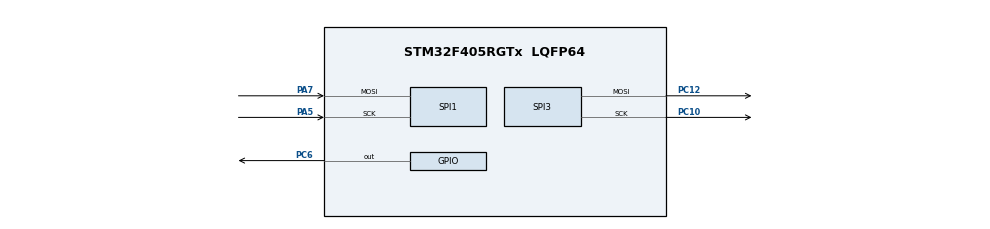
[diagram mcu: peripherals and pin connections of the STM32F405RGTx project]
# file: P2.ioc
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Mcu.Family=STM32F4
Mcu.Name=STM32F405RGTx
Mcu.Package=LQFP64
NVIC.PriorityGroup=NVIC_PRIORITYGROUP_4
PA5.Mode=RX_Only_Simplex_Unidirect_Slave
PA5.Signal=SPI1_SCK
PA7.Mode=RX_Only_Simplex_Unidirect_Slave
PA7.Signal=SPI1_MOSI
PC10.Mode=TX_Only_Simplex_Unidirect_Master
PC10.Signal=SPI3_SCK
PC12.Mode=TX_Only_Simplex_Unidirect_Master
PC12.Signal=SPI3_MOSI
PC6.Signal=GPIO_Output
ProjectManager.TargetToolchain=EWARM 6.70
RCC.48MHZClocksFreq_Value=48000000
RCC.AHBFreq_Value=16000000
RCC.APB1Freq_Value=16000000
RCC.APB2Freq_Value=16000000
RCC.EnableExtClockForI2S-ClockTree=false
RCC.EnableHSE-ClockTree=false
RCC.EnableHSERTCDevisor-ClockTree=false
RCC.EnableLSE-ClockTree=false
RCC.EnableLSERTC-ClockTree=false
RCC.ExtClockEnable-ClockTree=false
RCC.FLatency-AdvancedSettings=FLASH_LATENCY_0
RCC.HSEState-ClockTree=RCC_HSE_OFF
RCC.HSE_VALUE=25000000
RCC.HSIState-ClockTree=RCC_HSI_ON
RCC.HSI_VALUE=16000000
RCC.I2SEnable-ClockTree=false
RCC.IWDGEnable-ClockTree=false
RCC.LSE_VALUE=32768
RCC.LSIState-ClockTree=RCC_LSI_OFF
RCC.MCO1OutPutEnable-ClockTree=false
RCC.MCO2OutPutEnable-ClockTree=false
RCC.OscillatorTypeHSI-ClockTree=RCC_OSCILLATORTYPE_HSI
RCC.PLLState-ClockTree=RCC_PLL_OFF
RCC.PWR_Regulator_Voltage_Scale-AdvancedSettings=PWR_REGULATOR_VOLTAGE_SCALE2
RCC.RNGEnable-ClockTree=false
RCC.RTCEnable-ClockTree=false
RCC.SDIOEnable-ClockTree=false
RCC.SYSCLKFreq_VALUE=16000000
RCC.USBFSEnable-ClockTree=false
RCC.USBHSEnable-ClockTree=false
RCC.VCOOutputFreq_Value=192000000
SPI1.CalculateBaudRate-RX_Only_Simplex_Unidirect_Slave=8.0 MBits/s
SPI1.Direction-RX_Only_Simplex_Unidirect_Slave=SPI_DIRECTION_2LINES_RXONLY
SPI1.Mode-RX_Only_Simplex_Unidirect_Slave=SPI_MODE_SLAVE
SPI1.NSS-RX_Only_Simplex_Unidirect_Slave=SPI_NSS_SOFT
SPI1.TIMode-RX_Only_Simplex_Unidirect_Slave=SPI_TIMODE_DISABLED
SPI1.VirtualType-RX_Only_Simplex_Unidirect_Slave=VM_SLAVE
SPI3.CalculateBaudRate-TX_Only_Simplex_Unidirect_Master=8.0 MBits/s
SPI3.Direction-TX_Only_Simplex_Unidirect_Master=SPI_DIRECTION_2LINES
SPI3.Mode-TX_Only_Simplex_Unidirect_Master=SPI_MODE_MASTER
SPI3.NSS-TX_Only_Simplex_Unidirect_Master=SPI_NSS_SOFT
SPI3.TIMode-TX_Only_Simplex_Unidirect_Master=SPI_TIMODE_DISABLED
SPI3.VirtualType-TX_Only_Simplex_Unidirect_Master=VM_MASTER

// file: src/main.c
/**
  ******************************************************************************
  * File Name          : main.c
  * Date               : 08/11/2014 18:13:44
  * Description        : Main program body
  ******************************************************************************
  *
  * COPYRIGHT(c) 2014 STMicroelectronics
  *
  * Redistribution and use in source and binary forms, with or without modification,
  * are permitted provided that the following conditions are met:
  *   1. Redistributions of source code must retain the above copyright notice,
  *      this list of conditions and the following disclaimer.
  *   2. Redistributions in binary form must reproduce the above copyright notice,
  *      this list of conditions and the following disclaimer in the documentation
  *      and/or other materials provided with the distribution.
  *   3. Neither the name of STMicroelectronics nor the names of its contributors
  *      may be used to endorse or promote products derived from this software
  *      without specific prior written permission.
  *
  * THIS SOFTWARE IS PROVIDED BY THE COPYRIGHT HOLDERS AND CONTRIBUTORS "AS IS"
  * AND ANY EXPRESS OR IMPLIED WARRANTIES, INCLUDING, BUT NOT LIMITED TO, THE
  * IMPLIED WARRANTIES OF MERCHANTABILITY AND FITNESS FOR A PARTICULAR PURPOSE ARE
  * DISCLAIMED. IN NO EVENT SHALL THE COPYRIGHT HOLDER OR CONTRIBUTORS BE LIABLE
  * FOR ANY DIRECT, INDIRECT, INCIDENTAL, SPECIAL, EXEMPLARY, OR CONSEQUENTIAL
  * DAMAGES (INCLUDING, BUT NOT LIMITED TO, PROCUREMENT OF SUBSTITUTE GOODS OR
  * SERVICES; LOSS OF USE, DATA, OR PROFITS; OR BUSINESS INTERRUPTION) HOWEVER
  * CAUSED AND ON ANY THEORY OF LIABILITY, WHETHER IN CONTRACT, STRICT LIABILITY,
  * OR TORT (INCLUDING NEGLIGENCE OR OTHERWISE) ARISING IN ANY WAY OUT OF THE USE
  * OF THIS SOFTWARE, EVEN IF ADVISED OF THE POSSIBILITY OF SUCH DAMAGE.
  *
  ******************************************************************************
  */

#include "stm32f4xx_hal.h"

/* USER CODE BEGIN Includes */
#include <stdio.h>
/* USER CODE END Includes */

SPI_HandleTypeDef hspi1;
SPI_HandleTypeDef hspi3;

/* USER CODE BEGIN PV */
uint8_t x;
/* USER CODE END PV */

void SystemClock_Config(void);
static void MX_GPIO_Init(void);
static void MX_SPI1_Init(void);
static void MX_SPI3_Init(void);

int main(void)
{

  /* MCU Configuration----------------------------------------------------------*/

  /* Reset of all peripherals, Initializes the Flash interface and the Systick. */
  HAL_Init();

  /* Configure the system clock */
  SystemClock_Config();

  /* Initialize all configured peripherals */
  MX_GPIO_Init();
  MX_SPI1_Init();
  MX_SPI3_Init();

  /* USER CODE BEGIN 2 */
	HAL_Delay(1000);
	HAL_GPIO_WritePin(GPIOC,GPIO_PIN_6,GPIO_PIN_RESET);
  /* USER CODE END 2 */

  /* USER CODE BEGIN 3 */
	/* Infinite loop */
	while (1)
	{
		uint8_t i;
		for (i=1; i<9; i++)
		{
			uint8_t y = 66;
			//HAL_SPI_Transmit(&hspi3,&y,sizeof(int),0x1000);
			HAL_SPI_Receive(&hspi1,&y,sizeof(y),0x100);
			printf("Message=%i\n",y);
		}
	}
  /* USER CODE END 3 */

}

/** System Clock Configuration
*/
void SystemClock_Config(void)
{

  RCC_OscInitTypeDef RCC_OscInitStruct;

  __PWR_CLK_ENABLE();

  __HAL_PWR_VOLTAGESCALING_CONFIG(PWR_REGULATOR_VOLTAGE_SCALE2);

  RCC_OscInitStruct.OscillatorType = RCC_OSCILLATORTYPE_HSI;
  RCC_OscInitStruct.HSIState = RCC_HSI_ON;
  RCC_OscInitStruct.HSICalibrationValue = 6;
  RCC_OscInitStruct.PLL.PLLState = RCC_PLL_NONE;
  HAL_RCC_OscConfig(&RCC_OscInitStruct);

}

/* SPI1 init function */
void MX_SPI1_Init(void)
{

  hspi1.Instance = SPI1;
  hspi1.Init.Mode = SPI_MODE_SLAVE;
  hspi1.Init.Direction = SPI_DIRECTION_2LINES_RXONLY;
  hspi1.Init.DataSize = SPI_DATASIZE_8BIT;
  hspi1.Init.CLKPolarity = SPI_POLARITY_LOW;
  hspi1.Init.CLKPhase = SPI_PHASE_1EDGE;
  hspi1.Init.NSS = SPI_NSS_SOFT;
  hspi1.Init.BaudRatePrescaler = SPI_BAUDRATEPRESCALER_2;
  hspi1.Init.FirstBit = SPI_FIRSTBIT_MSB;
  hspi1.Init.TIMode = SPI_TIMODE_DISABLED;
  hspi1.Init.CRCCalculation = SPI_CRCCALCULATION_DISABLED;
  HAL_SPI_Init(&hspi1);

}

/* SPI3 init function */
void MX_SPI3_Init(void)
{

  hspi3.Instance = SPI3;
  hspi3.Init.Mode = SPI_MODE_MASTER;
  hspi3.Init.Direction = SPI_DIRECTION_2LINES;
  hspi3.Init.DataSize = SPI_DATASIZE_8BIT;
  hspi3.Init.CLKPolarity = SPI_POLARITY_LOW;
  hspi3.Init.CLKPhase = SPI_PHASE_1EDGE;
  hspi3.Init.NSS = SPI_NSS_SOFT;
  hspi3.Init.BaudRatePrescaler = SPI_BAUDRATEPRESCALER_2;
  hspi3.Init.FirstBit = SPI_FIRSTBIT_MSB;
  hspi3.Init.TIMode = SPI_TIMODE_DISABLED;
  hspi3.Init.CRCCalculation = SPI_CRCCALCULATION_DISABLED;
  HAL_SPI_Init(&hspi3);

}

/** Configure pins as
        * Analog
        * Input
        * Output
        * EVENT_OUT
        * EXTI
*/
void MX_GPIO_Init(void)
{

  GPIO_InitTypeDef GPIO_InitStruct;

  /* GPIO Ports Clock Enable */
  __GPIOA_CLK_ENABLE();
  __GPIOC_CLK_ENABLE();

  /*Configure GPIO pin : PC6 */
  GPIO_InitStruct.Pin = GPIO_PIN_6;
  GPIO_InitStruct.Mode = GPIO_MODE_OUTPUT_PP;
  GPIO_InitStruct.Pull = GPIO_NOPULL;
  GPIO_InitStruct.Speed = GPIO_SPEED_LOW;
  HAL_GPIO_Init(GPIOC, &GPIO_InitStruct);

}

/************************ (C) COPYRIGHT STMicroelectronics *****END OF FILE****/
